# LPC15xx register map
File version: 0.7
CPU: CM3 r2p1, little endian, no MPU, no FPU, 3 interrupt priority bits
Registers are 32-bit, read-write, reset 0x0 unless marked. A register's access mark holds for its fields unless they carry their own. Offsets are from the block's base; [hi:lo] are bit positions; {n}, {i} and the like mark numbered series.

## SWM — Switch Matrix (SWM)
Base 0x40038000
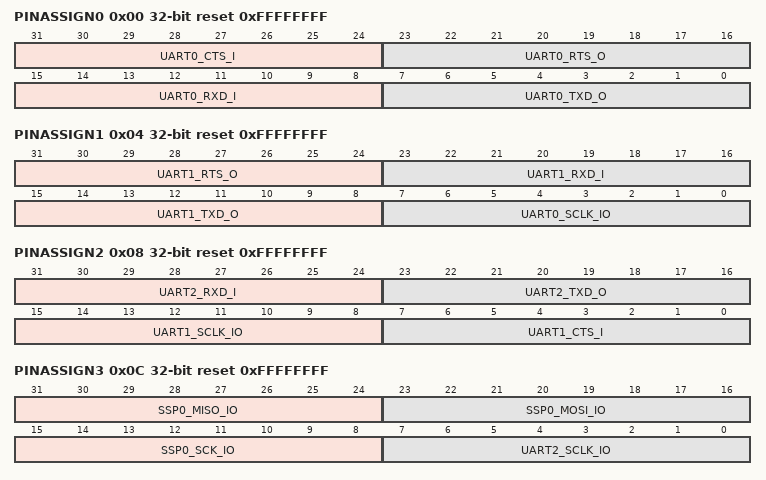
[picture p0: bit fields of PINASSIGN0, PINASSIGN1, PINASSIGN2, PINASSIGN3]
0x00 PINASSIGN0 reset 0xFFFFFFFF — Pin assign register 0. Assign movable functions U0_TXD, U0_RXD, U0_RTS, U0_CTS.
  [31:24] UART0_CTS_I — UART0_CTS function assignment. The value is the pin number to be assigned to this function. PIO0_0 = 0, ..., PIO1_0 = 32, ..., PIO2_11 = 75.
  [23:16] UART0_RTS_O — UART0_RTS function assignment. The value is the pin number to be assigned to this function. PIO0_0 = 0, ..., PIO1_0 = 32, ..., PIO2_11 = 75.
  [15:8] UART0_RXD_I — UART0_RXD function assignment. The value is the pin number to be assigned to this function. PIO0_0 = 0, ..., PIO1_0 = 32, ..., PIO2_11 = 75.
  [7:0] UART0_TXD_O — UART0_TXD function assignment. The value is the pin number to be assigned to this function. PIO0_0 = 0, ..., PIO1_0 = 32, ..., PIO2_11 = 75.
0x04 PINASSIGN1 reset 0xFFFFFFFF — Pin assign register 1. Assign movable functions U0_SCLK, U1_TXD, U1_RXD, U1_RTS.
  [31:24] UART1_RTS_O — UART1_RTS function assignment. The value is the pin number to be assigned to this function. PIO0_0 = 0, ..., PIO1_0 = 32, ..., PIO2_11 = 75.
  [23:16] UART1_RXD_I — UART1_RXD function assignment. The value is the pin number to be assigned to this function. PIO0_0 = 0, ..., PIO1_0 = 32, ..., PIO2_11 = 75.
  [15:8] UART1_TXD_O — UART1_TXD function assignment. The value is the pin number to be assigned to this function. PIO0_0 = 0, ..., PIO1_0 = 32, ..., PIO2_11 = 75.
  [7:0] UART0_SCLK_IO — UART0_SCLK function assignment. The value is the pin number to be assigned to this function. PIO0_0 = 0, ..., PIO1_0 = 32, ..., PIO2_11 = 75.
0x08 PINASSIGN2 reset 0xFFFFFFFF — Pin assign register 2. Assign movable functions U1_CTS, U1_SCLK, U2_TXD, U2_RXD.
  [31:24] UART2_RXD_I — UART2_RXD function assignment. The value is the pin number to be assigned to this function. PIO0_0 = 0, ..., PIO1_0 = 32, ..., PIO2_11 = 75.
  [23:16] UART2_TXD_O — UART2_TXD function assignment. The value is the pin number to be assigned to this function. PIO0_0 = 0, ..., PIO1_0 = 32, ..., PIO2_11 = 75.
  [15:8] UART1_SCLK_IO — UART1_SCLK function assignment. The value is the pin number to be assigned to this function. PIO0_0 = 0, ..., PIO1_0 = 32, ..., PIO2_11 = 75.
  [7:0] UART1_CTS_I — UART1_CTS function assignment. The value is the pin number to be assigned to this function. PIO0_0 = 0, ..., PIO1_0 = 32, ..., PIO2_11 = 75.
0x0C PINASSIGN3 reset 0xFFFFFFFF — Pin assign register 3. Assign movable function .
  [31:24] SSP0_MISO_IO — SSP0_MISO function assignment. The value is the pin number to be assigned to this function. PIO0_0 = 0, ..., PIO1_0 = 32, ..., PIO2_11 = 75.
  [23:16] SSP0_MOSI_IO — SSP0_MOSI function assignment. The value is the pin number to be assigned to this function. PIO0_0 = 0, ..., PIO1_0 = 32, ..., PIO2_11 = 75.
  [15:8] SSP0_SCK_IO — SSP0_SCK function assignment. The value is the pin number to be assigned to this function. PIO0_0 = 0, ..., PIO1_0 = 32, ..., PIO2_11 = 75.
  [7:0] UART2_SCLK_IO — UART2_SCLK function assignment. The value is the pin number to be assigned to this function. PIO0_0 = 0, ..., PIO1_0 = 32, ..., PIO2_11 = 75.
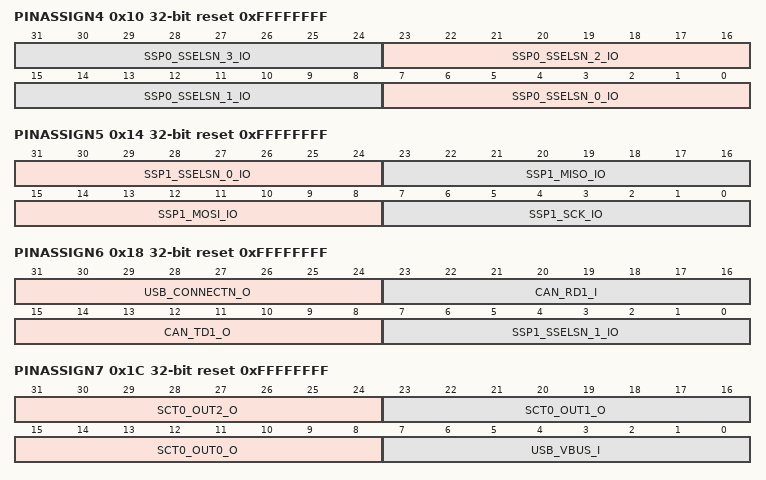
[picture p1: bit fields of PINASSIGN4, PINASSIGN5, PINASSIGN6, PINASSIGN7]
0x10 PINASSIGN4 reset 0xFFFFFFFF — Pin assign register 4. Assign movable functions
  [8n+7:8n] SSP0_SSELSN_{n}_IO (n=0..3) — SSP0_SSELSN_{n} function assignment. The value is the pin number to be assigned to this function. PIO0_0 = 0, ..., PIO1_0 = 32, ..., PIO2_11 = 75.
0x14 PINASSIGN5 reset 0xFFFFFFFF — Pin assign register 5. Assign movable functions
  [31:24] SSP1_SSELSN_0_IO — SSP1_SSELSN_0 function assignment. The value is the pin number to be assigned to this function. PIO0_0 = 0, ..., PIO1_0 = 32, ..., PIO2_11 = 75.
  [23:16] SSP1_MISO_IO — SSP1_MISO function assignment. The value is the pin number to be assigned to this function. PIO0_0 = 0, ..., PIO1_0 = 32, ..., PIO2_11 = 75.
  [15:8] SSP1_MOSI_IO — SSP1_MOSI function assignment. The value is the pin number to be assigned to this function. PIO0_0 = 0, ..., PIO1_0 = 32, ..., PIO2_11 = 75.
  [7:0] SSP1_SCK_IO — SSP1_SCK function assignment. The value is the pin number to be assigned to this function. PIO0_0 = 0, ..., PIO1_0 = 32, ..., PIO2_11 = 75.
0x18 PINASSIGN6 reset 0xFFFFFFFF — Pin assign register 6. Assign movable functions
  [31:24] USB_CONNECTN_O — USB_CONNECTN function assignment. The value is the pin number to be assigned to this function. PIO0_0 = 0, ..., PIO1_0 = 32, ..., PIO2_11 = 75.
  [23:16] CAN_RD1_I — CAN_RD1 function assignment. The value is the pin number to be assigned to this function. PIO0_0 = 0, ..., PIO1_0 = 32, ..., PIO2_11 = 75.
  [15:8] CAN_TD1_O — CAN_TD1 function assignment. The value is the pin number to be assigned to this function. PIO0_0 = 0, ..., PIO1_0 = 32, ..., PIO2_11 = 75.
  [7:0] SSP1_SSELSN_1_IO — SSP1_SSELSN_1 function assignment. The value is the pin number to be assigned to this function. PIO0_0 = 0, ..., PIO1_0 = 32, ..., PIO2_11 = 75.
0x1C PINASSIGN7 reset 0xFFFFFFFF — Pin assign register 7. Assign movable functions
  [31:24] SCT0_OUT2_O — SCT0_OUT2 function assignment. The value is the pin number to be assigned to this function. PIO0_0 = 0, ..., PIO1_0 = 32, ..., PIO2_11 = 75.
  [23:16] SCT0_OUT1_O — SCT0_OUT1 function assignment. The value is the pin number to be assigned to this function. PIO0_0 = 0, ..., PIO1_0 = 32, ..., PIO2_11 = 75.
  [15:8] SCT0_OUT0_O — SCT0_OUT0 function assignment. The value is the pin number to be assigned to this function. PIO0_0 = 0, ..., PIO1_0 = 32, ..., PIO2_11 = 75.
  [7:0] USB_VBUS_I — USB_VBUS function assignment. The value is the pin number to be assigned to this function. PIO0_0 = 0, ..., PIO1_0 = 32, ..., PIO2_11 = 75.
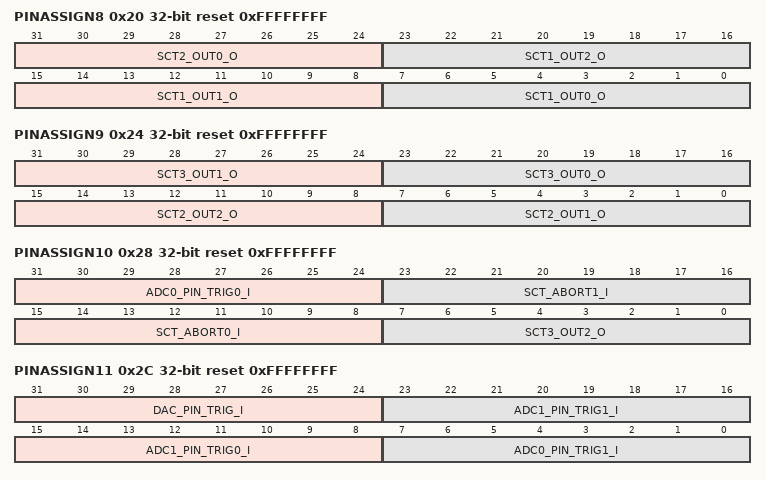
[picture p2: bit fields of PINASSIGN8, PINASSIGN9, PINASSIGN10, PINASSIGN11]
0x20 PINASSIGN8 reset 0xFFFFFFFF — Pin assign register 8. Assign movable functions
  [31:24] SCT2_OUT0_O — SCT2_OUT0 function assignment. The value is the pin number to be assigned to this function. PIO0_0 = 0, ..., PIO1_0 = 32, ..., PIO2_11 = 75.
  [23:16] SCT1_OUT2_O — SCT1_OUT2 function assignment. The value is the pin number to be assigned to this function. PIO0_0 = 0, ..., PIO1_0 = 32, ..., PIO2_11 = 75.
  [15:8] SCT1_OUT1_O — SCT1_OUT1 function assignment. The value is the pin number to be assigned to this function. PIO0_0 = 0, ..., PIO1_0 = 32, ..., PIO2_11 = 75.
  [7:0] SCT1_OUT0_O — SCT1_OUT0 function assignment. The value is the pin number to be assigned to this function. PIO0_0 = 0, ..., PIO1_0 = 32, ..., PIO2_11 = 75.
0x24 PINASSIGN9 reset 0xFFFFFFFF — Pin assign register 9. Assign movable functions
  [31:24] SCT3_OUT1_O — SCT3_OUT1 function assignment. The value is the pin number to be assigned to this function. PIO0_0 = 0, ..., PIO1_0 = 32, ..., PIO2_11 = 75.
  [23:16] SCT3_OUT0_O — SCT3_OUT0 function assignment. The value is the pin number to be assigned to this function. PIO0_0 = 0, ..., PIO1_0 = 32, ..., PIO2_11 = 75.
  [15:8] SCT2_OUT2_O — SCT2_OUT2 function assignment. The value is the pin number to be assigned to this function. PIO0_0 = 0, ..., PIO1_0 = 32, ..., PIO2_11 = 75.
  [7:0] SCT2_OUT1_O — SCT2_OUT1 function assignment. The value is the pin number to be assigned to this function. PIO0_0 = 0, ..., PIO1_0 = 32, ..., PIO2_11 = 75.
0x28 PINASSIGN10 reset 0xFFFFFFFF — Pin assign register 10. Assign movable functions
  [31:24] ADC0_PIN_TRIG0_I — ADC0_PIN_TRIG0 function assignment. The value is the pin number to be assigned to this function. PIO0_0 = 0, ..., PIO1_0 = 32, ..., PIO2_11 = 75.
  [23:16] SCT_ABORT1_I — SCT_ABORT1 function assignment. The value is the pin number to be assigned to this function. PIO0_0 = 0, ..., PIO1_0 = 32, ..., PIO2_11 = 75.
  [15:8] SCT_ABORT0_I — SCT_ABORT0 function assignment. The value is the pin number to be assigned to this function. PIO0_0 = 0, ..., PIO1_0 = 32, ..., PIO2_11 = 75.
  [7:0] SCT3_OUT2_O — SCT3_OUT2 function assignment. The value is the pin number to be assigned to this function. PIO0_0 = 0, ..., PIO1_0 = 32, ..., PIO2_11 = 75.
0x2C PINASSIGN11 reset 0xFFFFFFFF — Pin assign register 11. Assign movable functions
  [31:24] DAC_PIN_TRIG_I — DAC_PIN_TRIG function assignment. The value is the pin number to be assigned to this function. PIO0_0 = 0, ..., PIO1_0 = 32, ..., PIO2_11 = 75.
  [23:16] ADC1_PIN_TRIG1_I — ADC1_PIN_TRIG1 function assignment. The value is the pin number to be assigned to this function. PIO0_0 = 0, ..., PIO1_0 = 32, ..., PIO2_11 = 75.
  [15:8] ADC1_PIN_TRIG0_I — ADC1_PIN_TRIG0 function assignment. The value is the pin number to be assigned to this function. PIO0_0 = 0, ..., PIO1_0 = 32, ..., PIO2_11 = 75.
  [7:0] ADC0_PIN_TRIG1_I — ADC0_PIN_TRIG1 function assignment. The value is the pin number to be assigned to this function. PIO0_0 = 0, ..., PIO1_0 = 32, ..., PIO2_11 = 75.
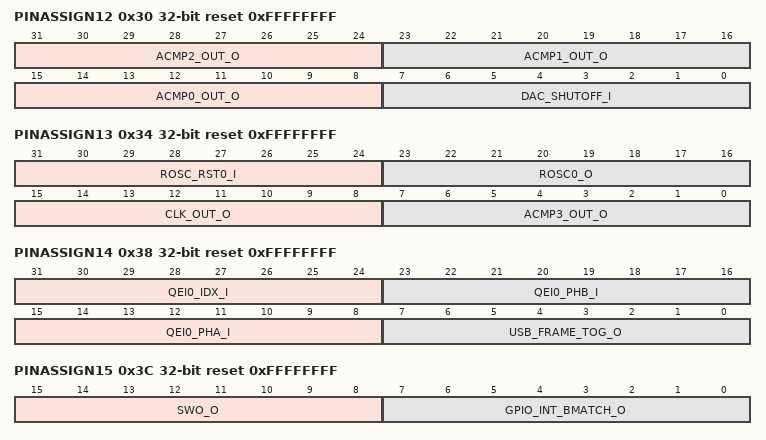
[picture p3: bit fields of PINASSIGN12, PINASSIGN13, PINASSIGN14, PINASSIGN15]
0x30 PINASSIGN12 reset 0xFFFFFFFF — Pin assign register 12. Assign movable functions
  [31:24] ACMP2_OUT_O — ACMP2_OUT function assignment. The value is the pin number to be assigned to this function. PIO0_0 = 0, ..., PIO1_0 = 32, ..., PIO2_11 = 75.
  [23:16] ACMP1_OUT_O — ACMP1_OUT function assignment. The value is the pin number to be assigned to this function. PIO0_0 = 0, ..., PIO1_0 = 32, ..., PIO2_11 = 75.
  [15:8] ACMP0_OUT_O — ACMP0_OUT function assignment. The value is the pin number to be assigned to this function. PIO0_0 = 0, ..., PIO1_0 = 32, ..., PIO2_11 = 75.
  [7:0] DAC_SHUTOFF_I — DAC_SHUTOFF function assignment. The value is the pin number to be assigned to this function. PIO0_0 = 0, ..., PIO1_0 = 32, ..., PIO2_11 = 75.
0x34 PINASSIGN13 reset 0xFFFFFFFF — Pin assign register 13. Assign movable functions
  [31:24] ROSC_RST0_I — ROSC_RST0 function assignment. The value is the pin number to be assigned to this function. PIO0_0 = 0, ..., PIO1_0 = 32, ..., PIO2_11 = 75.
  [23:16] ROSC0_O — ROSC0 function assignment. The value is the pin number to be assigned to this function. PIO0_0 = 0, ..., PIO1_0 = 32, ..., PIO2_11 = 75.
  [15:8] CLK_OUT_O — CLK_OUT function assignment. The value is the pin number to be assigned to this function. PIO0_0 = 0, ..., PIO1_0 = 32, ..., PIO2_11 = 75.
  [7:0] ACMP3_OUT_O — ACMP3_OUT function assignment. The value is the pin number to be assigned to this function. PIO0_0 = 0, ..., PIO1_0 = 32, ..., PIO2_11 = 75.
0x38 PINASSIGN14 reset 0xFFFFFFFF — Pin assign register 14. Assign movable functions
  [31:24] QEI0_IDX_I — QEI0_IDX function assignment. The value is the pin number to be assigned to this function. PIO0_0 = 0, ..., PIO1_0 = 32, ..., PIO2_11 = 75.
  [23:16] QEI0_PHB_I — QEI0_PHB function assignment. The value is the pin number to be assigned to this function. PIO0_0 = 0, ..., PIO1_0 = 32, ..., PIO2_11 = 75.
  [15:8] QEI0_PHA_I — QEI0_PHA function assignment. The value is the pin number to be assigned to this function. PIO0_0 = 0, ..., PIO1_0 = 32, ..., PIO2_11 = 75.
  [7:0] USB_FRAME_TOG_O — USB_FRAME_TOG function assignment. The value is the pin number to be assigned to this function. PIO0_0 = 0, ..., PIO1_0 = 32, ..., PIO2_11 = 75.
0x3C PINASSIGN15 reset 0xFFFFFFFF — Pin assign register 15. Assign movable functions
  [15:8] SWO_O — SWO function assignment. The value is the pin number to be assigned to this function. PIO0_0 = 0, ..., PIO1_0 = 32, ..., PIO2_11 = 75.
  [7:0] GPIO_INT_BMATCH_O — GPIO_INT_BMATCH function assignment. The value is the pin number to be assigned to this function. PIO0_0 = 0, ..., PIO1_0 = 32, ..., PIO2_11 = 75.
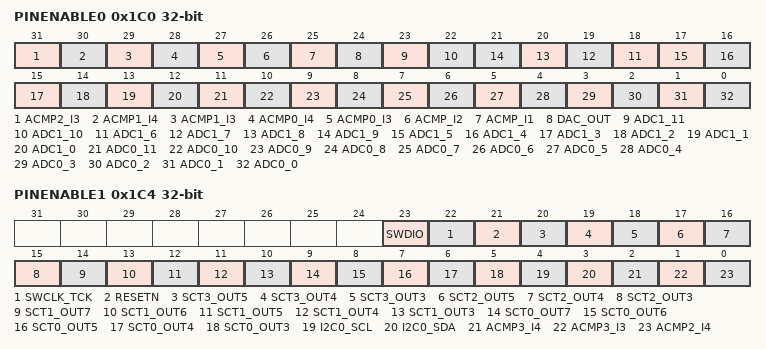
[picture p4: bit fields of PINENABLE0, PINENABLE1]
0x1C0 PINENABLE0 reset not defined — Pin enable register 0. Enables fixed-pin functions
  [31] ACMP2_I3 — Analog comparator 2 input 3 pin enable.
    0=ENABLED_ON_PIN_P0_29; 1=DISABLED
  [30] ACMP1_I4 — Analog comparator 1 input 4 pin enable.
    0=ENABLED_ON_PIN_P1_10; 1=DISABLED
  [29] ACMP1_I3 — Analog comparator 1 input 3 pin enable.
    0=ENABLED_ON_PIN_P0_28; 1=DISABLED
  [28] ACMP0_I4 — Analog comparator 0 input 4 pin enable.
    0=ENABLED_ON_PIN_P0_25; 1=DISABLED
  [27] ACMP0_I3 — Analog comparator 0 input 3 pin enable.
    0=ENABLED_ON_PIN_P0_26; 1=DISABLED
  [26] ACMP_I2 — ACMP input 2 (common input) pin enable.
    0=ENABLED_ON_PIN_P1_06; 1=DISABLED
  [25] ACMP_I1 — ACMP input 1 (common input) pin enable.
    0=ENABLED_ON_PIN_P0_27; 1=DISABLED
  [24] DAC_OUT — DAC_OUT pin enable.
    0=ENABLED_ON_PIN_P0_12; 1=DISABLED
  [23] ADC1_11 — ADC1_11 pin enable.
    0=ENABLED_ON_PIN_P1_05; 1=DISABLED
  [22] ADC1_10 — ADC1_10 pin enable.
    0=ENABLED_ON_PIN_P1_04; 1=DISABLED
  [n+12] ADC1_{n} (n=6..9) — ADC1_{n} pin enable.
    0=ENABLED_ON_PIN_P0_{n+7}; 1=DISABLED
  [17] ADC1_5 — ADC1_5 pin enable.
    0=ENABLED_ON_PIN_P1_03; 1=DISABLED
  [16] ADC1_4 — ADC1_4 pin enable.
    0=ENABLED_ON_PIN_P1_02; 1=DISABLED
  [15] ADC1_3 — ADC1_3 pin enable.
    0=ENABLED_ON_PIN_P0_11; 1=DISABLED
  [14] ADC1_2 — ADC1_2 pin enable.
    0=ENABLED_ON_PIN_P0_10; 1=DISABLED
  [13] ADC1_1 — ADC1_1 pin enable.
    0=ENABLED_ON_PIN_P0_09; 1=DISABLED
  [12] ADC1_0 — ADC1_0 pin enable.
    0=ENABLED_ON_PIN_P1_01; 1=DISABLED
  [11] ADC0_11 — ADC0_11 pin enable.
    0=ENABLED_ON_PIN_P0_30; 1=DISABLED
  [10] ADC0_10 — ADC0_10 pin enable.
    0=ENABLED_ON_PIN_P0_00; 1=DISABLED
  [9] ADC0_9 — ADC0_9 pin enable.
    0=ENABLED_ON_PIN_P0_31; 1=DISABLED
  [8] ADC0_8 — ADC0_8 pin enable.
    0=ENABLED_ON_PIN_P1_00; 1=DISABLED
  [7] ADC0_7 — ADC0_7 pin enable.
    0=ENABLED_ON_PIN_P0_01; 1=DISABLED
  [6] ADC0_6 — ADC0_6 pin enable.
    0=ENABLED_ON_PIN_P0_02; 1=DISABLED
  [5] ADC0_5 — ADC0_5 pin enable.
    0=ENABLED_ON_PIN_P0_03; 1=DISABLED
  [4] ADC0_4 — ADC0_4 pin enable.
    0=ENABLED_ON_PIN_P0_04; 1=DISABLED
  [3] ADC0_3 — ADC0_3 pin enable.
    0=ENABLED_ON_PIN_P0_05; 1=DISABLED
  [2] ADC0_2 — ADC0_2 pin enable.
    0=ENABLED_ON_PIN_P0_06; 1=DISABLED
  [1] ADC0_1 — ADC0_1 pin enable.
    0=ENABLED_ON_PIN_P0_07; 1=DISABLED
  [0] ADC0_0 — ADC0_0 pin enable.
    0=ENABLED_ON_PIN_P0_08; 1=DISABLED
0x1C4 PINENABLE1 reset not defined — Pin enable register 0. Enables fixed-pin functions
  [23] SWDIO — SWDIO pin enable.
    0=ENABLED_ON_PIN_P0_20; 1=DISABLED
  [22] SWCLK_TCK — SWCLK_TCK pin enable.
    0=ENABLED_ON_PIN_P0_19; 1=DISABLED
  [21] RESETN — RESETN pin enable.
    0=ENABLED_ON_PIN_P0_21; 1=DISABLED
  [20] SCT3_OUT5 — SCT3_OUT5 pin enable.
    0=ENABLED_ON_PIN_P1_24; 1=DISABLED
  [19] SCT3_OUT4 — SCT3_OUT4 pin enable.
    0=ENABLED_ON_PIN_P1_08; 1=DISABLED
  [18] SCT3_OUT3 — SCT3_OUT3 pin enable.
    0=ENABLED_ON_PIN_P0_26; 1=DISABLED
  [17] SCT2_OUT5 — SCT2_OUT5 pin enable.
    0=ENABLED_ON_PIN_P1_20; 1=DISABLED
  [16] SCT2_OUT4 — SCT2_OUT4 pin enable.
    0=ENABLED_ON_PIN_P0_29; 1=DISABLED
  [15] SCT2_OUT3 — SCT2_OUT3 pin enable.
    0=ENABLED_ON_PIN_P0_06; 1=DISABLED
  [14] SCT1_OUT7 — SCT1_OUT7 pin enable.
    0=ENABLED_ON_PIN_P1_17; 1=DISABLED
  [13] SCT1_OUT6 — SCT1_OUT6 pin enable.
    0=ENABLED_ON_PIN_P0_20; 1=DISABLED
  [12] SCT1_OUT5 — SCT1_OUT5 pin enable.
    0=ENABLED_ON_PIN_P0_14; 1=DISABLED
  [11] SCT1_OUT4 — SCT1_OUT4 pin enable.
    0=ENABLED_ON_PIN_P0_03; 1=DISABLED
  [10] SCT1_OUT3 — SCT1_OUT3 pin enable.
    0=ENABLED_ON_PIN_P0_02; 1=DISABLED
  [9] SCT0_OUT7 — SCT0_OUT7 pin enable.
    0=ENABLED_ON_PIN_P1_14; 1=DISABLED
  [8] SCT0_OUT6 — SCT0_OUT6 pin enable.
    0=ENABLED_ON_PIN_P0_24; 1=DISABLED
  [7] SCT0_OUT5 — SCT0_OUT5 pin enable.
    0=ENABLED_ON_PIN_P0_18; 1=DISABLED
  [6] SCT0_OUT4 — SCT0_OUT4 pin enable.
    0=ENABLED_ON_PIN_P0_01; 1=DISABLED
  [5] SCT0_OUT3 — SCT0_OUT3 pin enable.
    0=ENABLED_ON_PIN_P0_00; 1=DISABLED
  [4] I2C0_SCL — I2C0_SCL pin enable.
    0=ENABLED_ON_PIN_P0_22; 1=DISABLED
  [3] I2C0_SDA — I2C0_SDA pin enable.
    0=ENABLED_ON_PIN_P0_23; 1=DISABLED
  [2] ACMP3_I4 — Analog comparator 3 input 4 pin enable.
    0=ENABLED_ON_PIN_P1_07; 1=DISABLED
  [1] ACMP3_I3 — Analog comparator 3 input 3 pin enable.
    0=ENABLED_ON_PIN_P1_08; 1=DISABLED
  [0] ACMP2_I4 — Analog comparator 2 input 4 pin enable.
    0=ENABLED_ON_PIN_P1_09; 1=DISABLED
